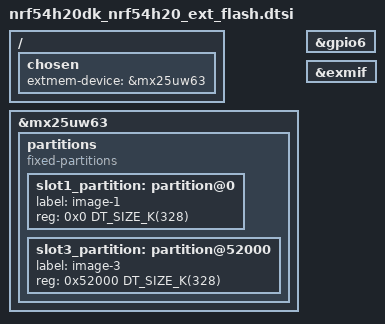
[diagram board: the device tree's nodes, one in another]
/*
 * Copyright (c) 2025 Nordic Semiconductor ASA
 *
 * SPDX-License-Identifier: LicenseRef-Nordic-5-Clause
 */

/delete-node/ &slot1_partition;
/delete-node/ &slot3_partition;

/ {
	chosen {
		extmem-device = &mx25uw63;
	};
};

&mx25uw63 {
	status = "okay";
	partitions {
		compatible = "fixed-partitions";
		#address-cells = <1>;
		#size-cells = <1>;

		slot1_partition: partition@0 {
			label = "image-1";
			reg = <0x0 DT_SIZE_K(328)>;
		};

		slot3_partition: partition@52000 {
			label = "image-3";
			reg = <0x52000 DT_SIZE_K(328)>;
		};
	};
};

&gpio6 {
	status = "okay";
};

&exmif {
	status = "okay";
};
